# Cortex_M35P register map
Vendor: Arm Ltd.; Series: ARMv8-M Mainline; File version: 1.0.0
CPU: CM35P r0p0, little endian, MPU, FPU, double-precision FPU, DSP, 8 interrupt priority bits
Registers are 32-bit, read-only, reset 0x0 unless marked. A register's access mark holds for its fields unless they carry their own. Offsets are from the block's base; [hi:lo] are bit positions; {n}, {i} and the like mark numbered series; 'fields as' and 'values as' point back to an identical list.

## MPU — Memory Protection Unit (optional): programmable regions with access permissions and memory attributes, checked on every access. ARMv6-M/v7-M (PMSAv7) use RBAR/RASR power-of-two regions; ARMv8-M (PMSAv8) uses RBAR/RLAR base-limit regions with MAIR attributes.
Base 0xE000ED90
Same registers: MPU_NS 0xE002ED90
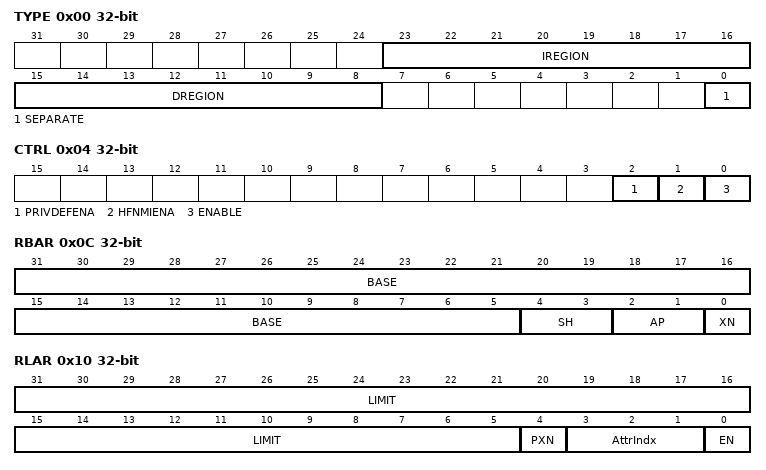
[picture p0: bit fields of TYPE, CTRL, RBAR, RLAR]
0x00 TYPE — MPU Type Register: how many regions the MPU implements (0 = no MPU). Read-only.
  [23:16] IREGION — Number of instruction regions; always 0 (unified).
  [15:8] DREGION — Number of MPU regions implemented (0 = no MPU; Cortex-M cores offer 8 or 16).
  [0] SEPARATE — 0 = unified MPU (instruction and data share the regions). Always 0 on Cortex-M.
0x04 CTRL rw — MPU Control Register: global enable, behaviour during HardFault/NMI, and the privileged default memory map.
  [2] PRIVDEFENA — 1 = privileged accesses to addresses not covered by any enabled region use the default memory map; 0 = they raise a MemManage fault (unprivileged accesses always fault).
  [1] HFNMIENA — 1 = the MPU stays enabled during HardFault, NMI and FAULTMASK handlers; 0 = those handlers use the default memory map (the usual choice).
  [0] ENABLE — MPU enable. When 0 the default memory map applies to all accesses.
0x08 RNR rw — MPU Region Number Register: selects the region that RBAR and RASR/RLAR access.
  [7:0] REGION — Region number selected for RBAR/RASR (RLAR) accesses.
0x0C RBAR rw — MPU Region Base Address Register for the region selected by RNR (ARMv7-M: also selects the region when VALID is set). ARMv8-M: base address, shareability, access permissions and XN.
  [31:5] BASE — Region start address bits [31:5] (32-byte granularity).
  [4:3] SH — Shareability of Normal memory: 0 = non-shareable, 2 = outer shareable, 3 = inner shareable (1 reserved). Ignored for Device memory.
    0=NonShareable; 2=OuterShareable; 3=InnerShareable
  [2:1] AP — Access permissions: 0 = read/write privileged only, 1 = read/write any privilege, 2 = read-only privileged only, 3 = read-only any privilege.
    0=RW_PRIV (Read/write, privileged only); 1=RW_ANY (Read/write, any privilege); 2=RO_PRIV (Read-only, privileged only); 3=RO_ANY (Read-only, any privilege)
  [0] XN — Execute never: 1 = instruction fetches from this region fault.
0x10 RLAR rw — MPU Region Limit Address Register (ARMv8-M PMSAv8): inclusive end address, attribute index into MAIR0/1 and enable of the selected region.
  [31:5] LIMIT — Region end address bits [31:5]; the low five bits are treated as 1, so the region is inclusive up to LIMIT + 31.
  [4] PXN — Privileged execute never (ARMv8.1-M): 1 = privileged instruction fetches from this region fault.
  [3:1] AttrIndx — Index (0-7) of the MAIR0/MAIR1 attribute byte that gives the memory type and cacheability of this region.
  [0] EN — Region enable.
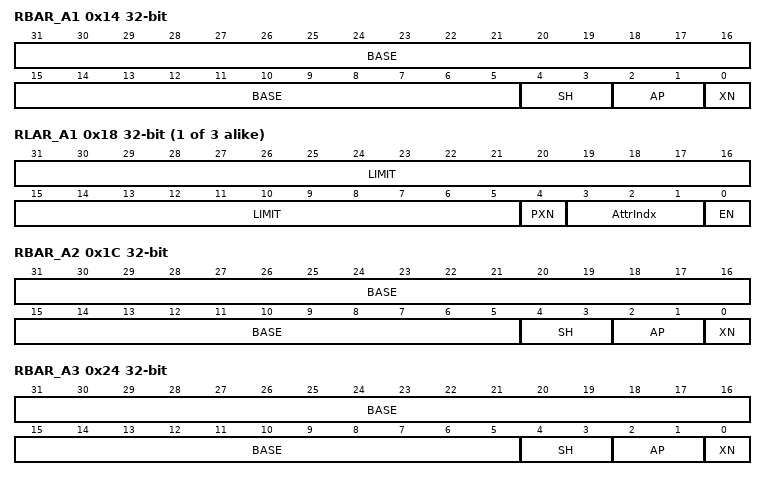
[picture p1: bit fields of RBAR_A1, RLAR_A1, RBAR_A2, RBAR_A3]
0x14 RBAR_A1 rw — Alias of RBAR that accesses region RNR+1, so up to four regions can be programmed with a single STM. Same fields as RBAR.
  fields as RBAR
{0x10+8i} RLAR_A{i} rw (i=1..3) — Alias of RLAR that accesses region RNR+{i}. Same fields as RLAR.
  fields as RLAR
0x1C RBAR_A2 rw — Alias of RBAR that accesses region RNR+2. Same fields as RBAR.
  fields as RBAR
0x24 RBAR_A3 rw — Alias of RBAR that accesses region RNR+3. Same fields as RBAR.
  fields as RBAR
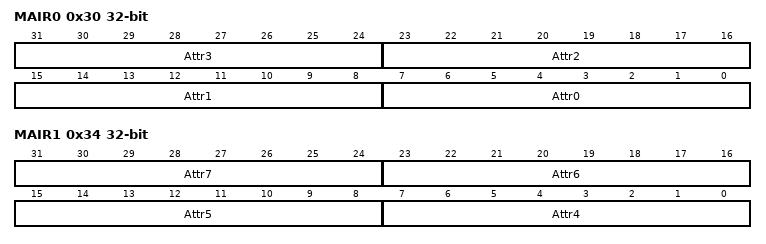
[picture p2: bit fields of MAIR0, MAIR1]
0x30 MAIR0 rw — MPU Memory Attribute Indirection Register 0: memory type/cacheability encodings 0-3 referenced by RLAR.AttrIndx.
  [8n+7:8n] Attr{n} (n=0..3) — Memory attribute encoding {n}, selected by RLAR.AttrIndx: Device memory = 0b0000dd00 (dd: 00 nGnRnE, 01 nGnRE, 10 nGRE, 11 GRE); Normal memory = outer[7:4] inner[3:0] with 0100 non-cacheable, 10RW write-through, 11RW write-back (R = read-allocate, W = write-allocate; 1111 = write-back RWA).
0x34 MAIR1 rw — MPU Memory Attribute Indirection Register 1: memory type/cacheability encodings 4-7 referenced by RLAR.AttrIndx.
  [8n-25:8n-32] Attr{n} (n=4..7) — Memory attribute encoding {n}, selected by RLAR.AttrIndx: Device memory = 0b0000dd00 (dd: 00 nGnRnE, 01 nGnRE, 10 nGRE, 11 GRE); Normal memory = outer[7:4] inner[3:0] with 0100 non-cacheable, 10RW write-through, 11RW write-back (R = read-allocate, W = write-allocate; 1111 = write-back RWA).
